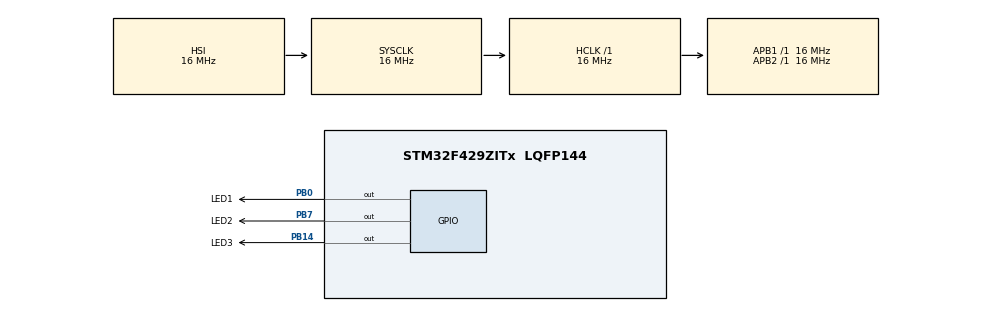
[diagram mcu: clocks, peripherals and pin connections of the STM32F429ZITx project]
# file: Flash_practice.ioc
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Mcu.Family=STM32F4
Mcu.Name=STM32F429ZITx
Mcu.Package=LQFP144
NVIC.PriorityGroup=NVIC_PRIORITYGROUP_4
PB0.GPIO_Label=LED1
PB0.Signal=GPIO_Output
PB14.GPIO_Label=LED3
PB14.Signal=GPIO_Output
PB7.GPIO_Label=LED2
PB7.Signal=GPIO_Output
ProjectManager.HeapSize=0x200
ProjectManager.StackSize=0x400
ProjectManager.TargetToolchain=STM32CubeIDE
RCC.AHBFreq_Value=16000000
RCC.APB1Freq_Value=16000000
RCC.APB2Freq_Value=16000000
RCC.CortexFreq_Value=16000000
RCC.HSE_VALUE=25000000
RCC.HSI_VALUE=16000000
RCC.LSE_VALUE=32768
RCC.SYSCLKFreq_VALUE=16000000
RCC.VCOOutputFreq_Value=192000000
board=custom

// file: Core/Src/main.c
/* USER CODE BEGIN Header */
/**
  ******************************************************************************
  * @file           : main.c
  * @brief          : Main program body
  ******************************************************************************
  * @attention
  *
  * Copyright (c) 2024 STMicroelectronics.
  * All rights reserved.
  *
  * This software is licensed under terms that can be found in the LICENSE file
  * in the root directory of this software component.
  * If no LICENSE file comes with this software, it is provided AS-IS.
  *
  ******************************************************************************
  */
/* USER CODE END Header */
#include "main.h"

/* USER CODE BEGIN PD */
#define ADDR_FLASH_SECTOR_0		((uint32_t)0x08000000)
#define ADDR_FLASH_SECTOR_1		((uint32_t)0x08004000)
#define ADDR_FLASH_SECTOR_2		((uint32_t)0x08008000)
#define ADDR_FLASH_SECTOR_3		((uint32_t)0x0800C000)
#define ADDR_FLASH_SECTOR_4		((uint32_t)0x08010000)
#define ADDR_FLASH_SECTOR_5		((uint32_t)0x08020000)
#define ADDR_FLASH_SECTOR_6		((uint32_t)0x08040000)
#define ADDR_FLASH_SECTOR_7		((uint32_t)0x08060000)
#define ADDR_FLASH_SECTOR_8		((uint32_t)0x08080000)
#define ADDR_FLASH_SECTOR_9		((uint32_t)0x080A0000)
#define ADDR_FLASH_SECTOR_10	((uint32_t)0x080C0000)
#define ADDR_FLASH_SECTOR_11	((uint32_t)0x080E0000)

#define FLASH_USER_START_ADDR	ADDR_FLASH_SECTOR_5
#define FLASH_USER_END_ADDR		ADDR_FLASH_SECTOR_8

#define DATA_32					((uint32_t)0x12345678)
/* USER CODE END PD */

void SystemClock_Config(void);
static void MX_GPIO_Init(void);

/* USER CODE BEGIN 0 */
static uint32_t GetSector(uint32_t Address);

uint32_t FirstSector = 0, NbOfSectors = 0, Address = 0;
uint32_t SectorError = 0;
__IO uint32_t data32 = 0, MemoryProgramStatus = 0;

static FLASH_EraseInitTypeDef EraseInitStruct;
/* USER CODE END 0 */

int main(void)
{

  /* MCU Configuration--------------------------------------------------------*/

  /* Reset of all peripherals, Initializes the Flash interface and the Systick. */
  HAL_Init();

  /* Configure the system clock */
  SystemClock_Config();

  /* Initialize all configured peripherals */
  MX_GPIO_Init();
  /* USER CODE BEGIN 2 */
  HAL_FLASH_Unlock();

  FirstSector = GetSector(FLASH_USER_START_ADDR);

  NbOfSectors = GetSector(FLASH_USER_END_ADDR) - FirstSector + 1;

  EraseInitStruct.TypeErase = TYPEERASE_SECTORS;
  EraseInitStruct.VoltageRange = VOLTAGE_RANGE_3;
  EraseInitStruct.Sector = FirstSector;
  EraseInitStruct.NbSectors = NbOfSectors;

  if(HAL_FLASHEx_Erase(&EraseInitStruct, &SectorError) != HAL_OK) {
	  Error_Handler();
  }

  Address = FLASH_USER_START_ADDR;

  while(Address < FLASH_USER_END_ADDR) {
	  if(HAL_FLASH_Program(TYPEPROGRAM_WORD, Address, DATA_32) == HAL_OK) {
		  Address = Address + 4;
	  }
	  else {
		  Error_Handler();
	  }
  }

  HAL_FLASH_Lock();

  HAL_GPIO_WritePin(GPIOB, LED2_Pin, 1);

  Address = FLASH_USER_START_ADDR;
  MemoryProgramStatus = 0x0;

  while(Address < FLASH_USER_END_ADDR) {
	  data32 = *(__IO uint32_t*)Address;
	  if(data32 != DATA_32) {
		  MemoryProgramStatus++;
	  }
	  Address = Address + 4;
  }

  if(MemoryProgramStatus == 0) {
	  HAL_GPIO_WritePin(GPIOB, LED1_Pin, 1);
  }
  else {
	  Error_Handler();
  }
  /* USER CODE END 2 */

  /* Infinite loop */
  while (1)
  {

  }
}

void SystemClock_Config(void)
{
  RCC_OscInitTypeDef RCC_OscInitStruct = {0};
  RCC_ClkInitTypeDef RCC_ClkInitStruct = {0};

  /** Configure the main internal regulator output voltage
  */
  __HAL_RCC_PWR_CLK_ENABLE();
  __HAL_PWR_VOLTAGESCALING_CONFIG(PWR_REGULATOR_VOLTAGE_SCALE3);

  /** Initializes the RCC Oscillators according to the specified parameters
  * in the RCC_OscInitTypeDef structure.
  */
  RCC_OscInitStruct.OscillatorType = RCC_OSCILLATORTYPE_HSI;
  RCC_OscInitStruct.HSIState = RCC_HSI_ON;
  RCC_OscInitStruct.HSICalibrationValue = RCC_HSICALIBRATION_DEFAULT;
  RCC_OscInitStruct.PLL.PLLState = RCC_PLL_NONE;
  if (HAL_RCC_OscConfig(&RCC_OscInitStruct) != HAL_OK)
  {
    Error_Handler();
  }

  /** Initializes the CPU, AHB and APB buses clocks
  */
  RCC_ClkInitStruct.ClockType = RCC_CLOCKTYPE_HCLK|RCC_CLOCKTYPE_SYSCLK
                              |RCC_CLOCKTYPE_PCLK1|RCC_CLOCKTYPE_PCLK2;
  RCC_ClkInitStruct.SYSCLKSource = RCC_SYSCLKSOURCE_HSI;
  RCC_ClkInitStruct.AHBCLKDivider = RCC_SYSCLK_DIV1;
  RCC_ClkInitStruct.APB1CLKDivider = RCC_HCLK_DIV1;
  RCC_ClkInitStruct.APB2CLKDivider = RCC_HCLK_DIV1;

  if (HAL_RCC_ClockConfig(&RCC_ClkInitStruct, FLASH_LATENCY_0) != HAL_OK)
  {
    Error_Handler();
  }
}

static void MX_GPIO_Init(void)
{
  GPIO_InitTypeDef GPIO_InitStruct = {0};

  /* GPIO Ports Clock Enable */
  __HAL_RCC_GPIOB_CLK_ENABLE();

  /*Configure GPIO pin Output Level */
  HAL_GPIO_WritePin(GPIOB, LED1_Pin|LED3_Pin|LED2_Pin, GPIO_PIN_RESET);

  /*Configure GPIO pins : LED1_Pin LED3_Pin LED2_Pin */
  GPIO_InitStruct.Pin = LED1_Pin|LED3_Pin|LED2_Pin;
  GPIO_InitStruct.Mode = GPIO_MODE_OUTPUT_PP;
  GPIO_InitStruct.Pull = GPIO_NOPULL;
  GPIO_InitStruct.Speed = GPIO_SPEED_FREQ_LOW;
  HAL_GPIO_Init(GPIOB, &GPIO_InitStruct);

}

/* USER CODE BEGIN 4 */
static uint32_t GetSector(uint32_t Address)
{
	uint32_t sector = 0;
	if((Address < ADDR_FLASH_SECTOR_1) && (Address >= ADDR_FLASH_SECTOR_0)) {
		sector = FLASH_SECTOR_0;
	}
	else if((Address < ADDR_FLASH_SECTOR_2) && (Address >= ADDR_FLASH_SECTOR_1)) {
		sector = FLASH_SECTOR_1;
	}
	else if((Address < ADDR_FLASH_SECTOR_3) && (Address >= ADDR_FLASH_SECTOR_2)) {
		sector = FLASH_SECTOR_2;
	}
	else if((Address < ADDR_FLASH_SECTOR_4) && (Address >= ADDR_FLASH_SECTOR_3)) {
		sector = FLASH_SECTOR_3;
	}
	else if((Address < ADDR_FLASH_SECTOR_5) && (Address >= ADDR_FLASH_SECTOR_4)) {
		sector = FLASH_SECTOR_4;
	}
	else if((Address < ADDR_FLASH_SECTOR_6) && (Address >= ADDR_FLASH_SECTOR_5)) {
		sector = FLASH_SECTOR_5;
	}
	else if((Address < ADDR_FLASH_SECTOR_7) && (Address >= ADDR_FLASH_SECTOR_6)) {
		sector = FLASH_SECTOR_6;
	}
	else if((Address < ADDR_FLASH_SECTOR_8) && (Address >= ADDR_FLASH_SECTOR_7)) {
		sector = FLASH_SECTOR_7;
	}
	else if((Address < ADDR_FLASH_SECTOR_9) && (Address >= ADDR_FLASH_SECTOR_8)) {
		sector = FLASH_SECTOR_8;
	}
	else if((Address < ADDR_FLASH_SECTOR_10) && (Address >= ADDR_FLASH_SECTOR_9)) {
		sector = FLASH_SECTOR_9;
	}
	else if((Address < ADDR_FLASH_SECTOR_11) && (Address >= ADDR_FLASH_SECTOR_10)) {
		sector = FLASH_SECTOR_10;
	}
	else {
		sector = FLASH_SECTOR_11;
	}
	return sector;
}
/* USER CODE END 4 */

void Error_Handler(void)
{
  __disable_irq();
  while (1)
  {
  }
}
